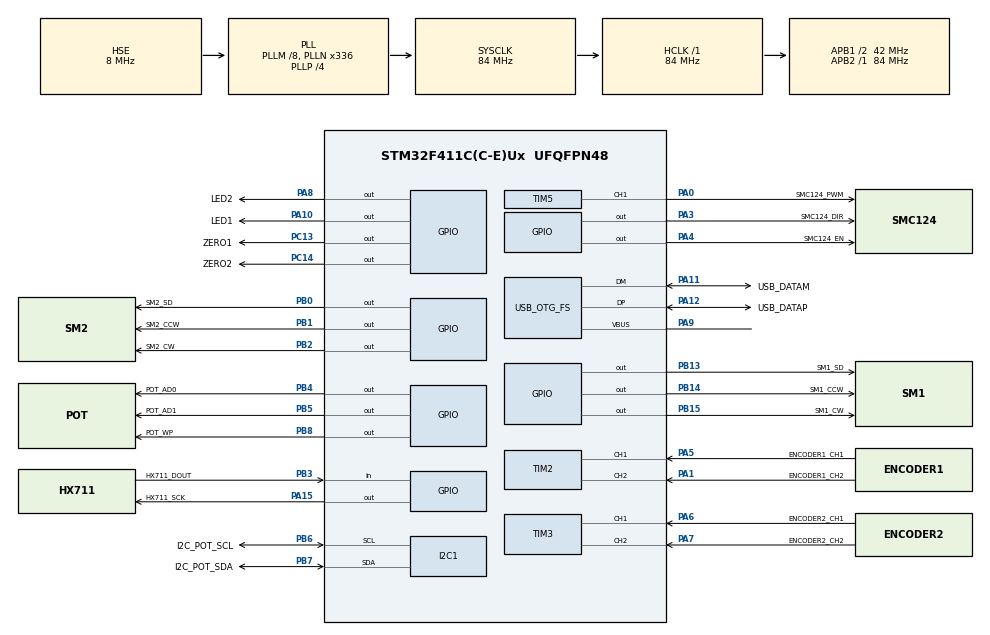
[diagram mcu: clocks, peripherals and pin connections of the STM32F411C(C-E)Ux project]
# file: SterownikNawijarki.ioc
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Mcu.Family=STM32F4
Mcu.Name=STM32F411C(C-E)Ux
Mcu.Package=UFQFPN48
NVIC.OTG_FS_IRQn=true\:0\:0\:false\:false\:true\:false\:true\:true
NVIC.PriorityGroup=NVIC_PRIORITYGROUP_4
NVIC.TIM4_IRQn=true\:0\:0\:false\:false\:true\:true\:true\:true
PA0-WKUP.GPIO_Label=SMC124_PWM
PA0-WKUP.Signal=S_TIM5_CH1
PA1.GPIO_Label=ENCODER1_CH2
PA1.Signal=S_TIM2_CH2
PA10.GPIO_Label=LED1
PA10.Signal=GPIO_Output
PA11.GPIO_Label=USB_DATAM
PA11.Mode=Device_Only
PA11.Signal=USB_OTG_FS_DM
PA12.GPIO_Label=USB_DATAP
PA12.Mode=Device_Only
PA12.Signal=USB_OTG_FS_DP
PA13.Mode=Serial_Wire
PA13.Signal=SYS_JTMS-SWDIO
PA14.Mode=Serial_Wire
PA14.Signal=SYS_JTCK-SWCLK
PA15.GPIO_Label=HX711_SCK
PA15.Signal=GPIO_Output
PA3.GPIO_Label=SMC124_DIR
PA3.Signal=GPIO_Output
PA4.GPIO_Label=SMC124_EN
PA4.Signal=GPIO_Output
PA5.GPIO_Label=ENCODER1_CH1
PA5.Signal=S_TIM2_CH1_ETR
PA6.GPIO_Label=ENCODER2_CH1
PA6.Signal=S_TIM3_CH1
PA7.GPIO_Label=ENCODER2_CH2
PA7.Signal=S_TIM3_CH2
PA8.GPIO_Label=LED2
PA8.Signal=GPIO_Output
PA9.Mode=Activate_VBUS
PA9.Signal=USB_OTG_FS_VBUS
PB0.GPIO_Label=SM2_SD
PB0.Signal=GPIO_Output
PB1.GPIO_Label=SM2_CCW
PB1.Signal=GPIO_Output
PB13.GPIO_Label=SM1_SD
PB13.Signal=GPIO_Output
PB14.GPIO_Label=SM1_CCW
PB14.Signal=GPIO_Output
PB15.GPIO_Label=SM1_CW
PB15.Signal=GPIO_Output
PB2.GPIO_Label=SM2_CW
PB2.Signal=GPIO_Output
PB3.GPIO_Label=HX711_DOUT
PB3.Signal=GPIO_Input
PB4.GPIO_Label=POT_AD0
PB4.Signal=GPIO_Output
PB5.GPIO_Label=POT_AD1
PB5.Signal=GPIO_Output
PB6.GPIO_Label=I2C_POT_SCL
PB6.Mode=I2C
PB6.Signal=I2C1_SCL
PB7.GPIO_Label=I2C_POT_SDA
PB7.Mode=I2C
PB7.Signal=I2C1_SDA
PB8.GPIO_Label=POT_WP
PB8.Signal=GPIO_Output
PC13-ANTI_TAMP.GPIO_Label=ZERO1
PC13-ANTI_TAMP.Signal=GPIO_Output
PC14-OSC32_IN.GPIO_Label=ZERO2
PC14-OSC32_IN.Signal=GPIO_Output
PH0\ -\ OSC_IN.GPIO_Label=OSC8M_IN
PH0\ -\ OSC_IN.Mode=HSE-External-Oscillator
PH0\ -\ OSC_IN.Signal=RCC_OSC_IN
PH1\ -\ OSC_OUT.GPIO_Label=OSC8M_OUT
PH1\ -\ OSC_OUT.Mode=HSE-External-Oscillator
PH1\ -\ OSC_OUT.Signal=RCC_OSC_OUT
ProjectManager.HeapSize=0x200
ProjectManager.StackSize=0x400
ProjectManager.TargetToolchain=STM32CubeIDE
RCC.48MHZClocksFreq_Value=48000000
RCC.AHBFreq_Value=84000000
RCC.APB1CLKDivider=RCC_HCLK_DIV2
RCC.APB1Freq_Value=42000000
RCC.APB1TimFreq_Value=84000000
RCC.APB2Freq_Value=84000000
RCC.APB2TimFreq_Value=84000000
RCC.CortexFreq_Value=84000000
RCC.HCLKFreq_Value=84000000
RCC.HSE_VALUE=8000000
RCC.HSI_VALUE=16000000
RCC.LSE_VALUE=32768
RCC.PLLM=8
RCC.PLLN=336
RCC.PLLP=RCC_PLLP_DIV4
RCC.PLLQ=7
RCC.SYSCLKFreq_VALUE=84000000
RCC.SYSCLKSource=RCC_SYSCLKSOURCE_PLLCLK
RCC.VCOOutputFreq_Value=336000000
SH.S_TIM2_CH1_ETR.0=TIM2_CH1,Encoder_Interface
SH.S_TIM2_CH2.0=TIM2_CH2,Encoder_Interface
SH.S_TIM3_CH1.0=TIM3_CH1,Encoder_Interface
SH.S_TIM3_CH2.0=TIM3_CH2,Encoder_Interface
SH.S_TIM5_CH1.0=TIM5_CH1,PWM Generation1 CH1
TIM4.AutoReloadPreload=TIM_AUTORELOAD_PRELOAD_ENABLE
TIM4.ClockDivision=TIM_CLOCKDIVISION_DIV4
TIM4.Period=9999
TIM4.Prescaler=8399
TIM5.Channel-PWM\ Generation1\ CH1=TIM_CHANNEL_1
TIM5.Period=99
TIM5.Prescaler=8
USB_DEVICE.CLASS_NAME_FS=CDC
USB_DEVICE.VirtualMode=Cdc
USB_DEVICE.VirtualModeFS=Cdc_FS
USB_OTG_FS.VirtualMode=Device_Only
VP_TIM4_VS_ClockSourceINT.Mode=Internal
VP_USB_DEVICE_VS_USB_DEVICE_CDC_FS.Mode=CDC_FS
board=custom

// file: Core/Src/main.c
/* USER CODE BEGIN Header */
/**
  ******************************************************************************
  * @file           : main.c
  * @brief          : Main program body
  ******************************************************************************
  * @attention
  *
  * Copyright (c) 2024 STMicroelectronics.
  * All rights reserved.
  *
  * This software is licensed under terms that can be found in the LICENSE file
  * in the root directory of this software component.
  * If no LICENSE file comes with this software, it is provided AS-IS.
  *
  ******************************************************************************
  */
/* USER CODE END Header */
#include "main.h"
#include "usb_device.h"

/* USER CODE BEGIN Includes */
#include "usbd_cdc_if.h"
#include "cdc_control.h"
#include "ad5254.h"
/* USER CODE END Includes */

I2C_HandleTypeDef hi2c1;

TIM_HandleTypeDef htim2;
TIM_HandleTypeDef htim3;
TIM_HandleTypeDef htim4;
TIM_HandleTypeDef htim5;

void SystemClock_Config(void);
static void MX_GPIO_Init(void);
static void MX_TIM2_Init(void);
static void MX_TIM3_Init(void);
static void MX_TIM5_Init(void);
static void MX_I2C1_Init(void);
static void MX_TIM4_Init(void);

int main(void)
{

  /* MCU Configuration--------------------------------------------------------*/

  /* Reset of all peripherals, Initializes the Flash interface and the Systick. */
  HAL_Init();

  /* Configure the system clock */
  SystemClock_Config();

  /* Initialize all configured peripherals */
  MX_GPIO_Init();
  MX_TIM2_Init();
  MX_TIM3_Init();
  MX_TIM5_Init();
  MX_USB_DEVICE_Init();
  MX_I2C1_Init();
  MX_TIM4_Init();

  /* Infinite loop */
  while (1)
  {

  }
}

void SystemClock_Config(void)
{
  RCC_OscInitTypeDef RCC_OscInitStruct = {0};
  RCC_ClkInitTypeDef RCC_ClkInitStruct = {0};

  /** Configure the main internal regulator output voltage
  */
  __HAL_RCC_PWR_CLK_ENABLE();
  __HAL_PWR_VOLTAGESCALING_CONFIG(PWR_REGULATOR_VOLTAGE_SCALE1);

  /** Initializes the RCC Oscillators according to the specified parameters
  * in the RCC_OscInitTypeDef structure.
  */
  RCC_OscInitStruct.OscillatorType = RCC_OSCILLATORTYPE_HSE;
  RCC_OscInitStruct.HSEState = RCC_HSE_ON;
  RCC_OscInitStruct.PLL.PLLState = RCC_PLL_ON;
  RCC_OscInitStruct.PLL.PLLSource = RCC_PLLSOURCE_HSE;
  RCC_OscInitStruct.PLL.PLLM = 8;
  RCC_OscInitStruct.PLL.PLLN = 336;
  RCC_OscInitStruct.PLL.PLLP = RCC_PLLP_DIV4;
  RCC_OscInitStruct.PLL.PLLQ = 7;
  if (HAL_RCC_OscConfig(&RCC_OscInitStruct) != HAL_OK)
  {
    Error_Handler();
  }

  /** Initializes the CPU, AHB and APB buses clocks
  */
  RCC_ClkInitStruct.ClockType = RCC_CLOCKTYPE_HCLK|RCC_CLOCKTYPE_SYSCLK
                              |RCC_CLOCKTYPE_PCLK1|RCC_CLOCKTYPE_PCLK2;
  RCC_ClkInitStruct.SYSCLKSource = RCC_SYSCLKSOURCE_PLLCLK;
  RCC_ClkInitStruct.AHBCLKDivider = RCC_SYSCLK_DIV1;
  RCC_ClkInitStruct.APB1CLKDivider = RCC_HCLK_DIV2;
  RCC_ClkInitStruct.APB2CLKDivider = RCC_HCLK_DIV1;

  if (HAL_RCC_ClockConfig(&RCC_ClkInitStruct, FLASH_LATENCY_2) != HAL_OK)
  {
    Error_Handler();
  }
}

static void MX_I2C1_Init(void)
{

  hi2c1.Instance = I2C1;
  hi2c1.Init.ClockSpeed = 100000;
  hi2c1.Init.DutyCycle = I2C_DUTYCYCLE_2;
  hi2c1.Init.OwnAddress1 = 0;
  hi2c1.Init.AddressingMode = I2C_ADDRESSINGMODE_7BIT;
  hi2c1.Init.DualAddressMode = I2C_DUALADDRESS_DISABLE;
  hi2c1.Init.OwnAddress2 = 0;
  hi2c1.Init.GeneralCallMode = I2C_GENERALCALL_DISABLE;
  hi2c1.Init.NoStretchMode = I2C_NOSTRETCH_DISABLE;
  if (HAL_I2C_Init(&hi2c1) != HAL_OK)
  {
    Error_Handler();
  }

}

static void MX_TIM2_Init(void)
{

  TIM_Encoder_InitTypeDef sConfig = {0};
  TIM_MasterConfigTypeDef sMasterConfig = {0};

  htim2.Instance = TIM2;
  htim2.Init.Prescaler = 0;
  htim2.Init.CounterMode = TIM_COUNTERMODE_UP;
  htim2.Init.Period = 4294967295;
  htim2.Init.ClockDivision = TIM_CLOCKDIVISION_DIV1;
  htim2.Init.AutoReloadPreload = TIM_AUTORELOAD_PRELOAD_DISABLE;
  sConfig.EncoderMode = TIM_ENCODERMODE_TI1;
  sConfig.IC1Polarity = TIM_ICPOLARITY_RISING;
  sConfig.IC1Selection = TIM_ICSELECTION_DIRECTTI;
  sConfig.IC1Prescaler = TIM_ICPSC_DIV1;
  sConfig.IC1Filter = 0;
  sConfig.IC2Polarity = TIM_ICPOLARITY_RISING;
  sConfig.IC2Selection = TIM_ICSELECTION_DIRECTTI;
  sConfig.IC2Prescaler = TIM_ICPSC_DIV1;
  sConfig.IC2Filter = 0;
  if (HAL_TIM_Encoder_Init(&htim2, &sConfig) != HAL_OK)
  {
    Error_Handler();
  }
  sMasterConfig.MasterOutputTrigger = TIM_TRGO_RESET;
  sMasterConfig.MasterSlaveMode = TIM_MASTERSLAVEMODE_DISABLE;
  if (HAL_TIMEx_MasterConfigSynchronization(&htim2, &sMasterConfig) != HAL_OK)
  {
    Error_Handler();
  }

}

static void MX_TIM3_Init(void)
{

  TIM_Encoder_InitTypeDef sConfig = {0};
  TIM_MasterConfigTypeDef sMasterConfig = {0};

  htim3.Instance = TIM3;
  htim3.Init.Prescaler = 0;
  htim3.Init.CounterMode = TIM_COUNTERMODE_UP;
  htim3.Init.Period = 65535;
  htim3.Init.ClockDivision = TIM_CLOCKDIVISION_DIV1;
  htim3.Init.AutoReloadPreload = TIM_AUTORELOAD_PRELOAD_DISABLE;
  sConfig.EncoderMode = TIM_ENCODERMODE_TI1;
  sConfig.IC1Polarity = TIM_ICPOLARITY_RISING;
  sConfig.IC1Selection = TIM_ICSELECTION_DIRECTTI;
  sConfig.IC1Prescaler = TIM_ICPSC_DIV1;
  sConfig.IC1Filter = 0;
  sConfig.IC2Polarity = TIM_ICPOLARITY_RISING;
  sConfig.IC2Selection = TIM_ICSELECTION_DIRECTTI;
  sConfig.IC2Prescaler = TIM_ICPSC_DIV1;
  sConfig.IC2Filter = 0;
  if (HAL_TIM_Encoder_Init(&htim3, &sConfig) != HAL_OK)
  {
    Error_Handler();
  }
  sMasterConfig.MasterOutputTrigger = TIM_TRGO_RESET;
  sMasterConfig.MasterSlaveMode = TIM_MASTERSLAVEMODE_DISABLE;
  if (HAL_TIMEx_MasterConfigSynchronization(&htim3, &sMasterConfig) != HAL_OK)
  {
    Error_Handler();
  }

}

static void MX_TIM4_Init(void)
{

  TIM_ClockConfigTypeDef sClockSourceConfig = {0};
  TIM_MasterConfigTypeDef sMasterConfig = {0};

  htim4.Instance = TIM4;
  htim4.Init.Prescaler = 8399;
  htim4.Init.CounterMode = TIM_COUNTERMODE_UP;
  htim4.Init.Period = 9999;
  htim4.Init.ClockDivision = TIM_CLOCKDIVISION_DIV4;
  htim4.Init.AutoReloadPreload = TIM_AUTORELOAD_PRELOAD_ENABLE;
  if (HAL_TIM_Base_Init(&htim4) != HAL_OK)
  {
    Error_Handler();
  }
  sClockSourceConfig.ClockSource = TIM_CLOCKSOURCE_INTERNAL;
  if (HAL_TIM_ConfigClockSource(&htim4, &sClockSourceConfig) != HAL_OK)
  {
    Error_Handler();
  }
  sMasterConfig.MasterOutputTrigger = TIM_TRGO_RESET;
  sMasterConfig.MasterSlaveMode = TIM_MASTERSLAVEMODE_DISABLE;
  if (HAL_TIMEx_MasterConfigSynchronization(&htim4, &sMasterConfig) != HAL_OK)
  {
    Error_Handler();
  }

}

static void MX_TIM5_Init(void)
{

  TIM_MasterConfigTypeDef sMasterConfig = {0};
  TIM_OC_InitTypeDef sConfigOC = {0};

  htim5.Instance = TIM5;
  htim5.Init.Prescaler = 8;
  htim5.Init.CounterMode = TIM_COUNTERMODE_UP;
  htim5.Init.Period = 99;
  htim5.Init.ClockDivision = TIM_CLOCKDIVISION_DIV1;
  htim5.Init.AutoReloadPreload = TIM_AUTORELOAD_PRELOAD_DISABLE;
  if (HAL_TIM_PWM_Init(&htim5) != HAL_OK)
  {
    Error_Handler();
  }
  sMasterConfig.MasterOutputTrigger = TIM_TRGO_RESET;
  sMasterConfig.MasterSlaveMode = TIM_MASTERSLAVEMODE_DISABLE;
  if (HAL_TIMEx_MasterConfigSynchronization(&htim5, &sMasterConfig) != HAL_OK)
  {
    Error_Handler();
  }
  sConfigOC.OCMode = TIM_OCMODE_PWM1;
  sConfigOC.Pulse = 0;
  sConfigOC.OCPolarity = TIM_OCPOLARITY_HIGH;
  sConfigOC.OCFastMode = TIM_OCFAST_DISABLE;
  if (HAL_TIM_PWM_ConfigChannel(&htim5, &sConfigOC, TIM_CHANNEL_1) != HAL_OK)
  {
    Error_Handler();
  }
  HAL_TIM_MspPostInit(&htim5);

}

static void MX_GPIO_Init(void)
{
  GPIO_InitTypeDef GPIO_InitStruct = {0};

  /* GPIO Ports Clock Enable */
  __HAL_RCC_GPIOC_CLK_ENABLE();
  __HAL_RCC_GPIOH_CLK_ENABLE();
  __HAL_RCC_GPIOA_CLK_ENABLE();
  __HAL_RCC_GPIOB_CLK_ENABLE();

  /*Configure GPIO pin Output Level */
  HAL_GPIO_WritePin(GPIOC, ZERO1_Pin|ZERO2_Pin, GPIO_PIN_RESET);

  /*Configure GPIO pin Output Level */
  HAL_GPIO_WritePin(GPIOA, SMC124_DIR_Pin|SMC124_EN_Pin|LED2_Pin|LED1_Pin
                          |HX711_SCK_Pin, GPIO_PIN_RESET);

  /*Configure GPIO pin Output Level */
  HAL_GPIO_WritePin(GPIOB, SM2_SD_Pin|SM2_CCW_Pin|SM2_CW_Pin|SM1_SD_Pin
                          |SM1_CCW_Pin|SM1_CW_Pin|POT_AD0_Pin|POT_AD1_Pin
                          |POT_WP_Pin, GPIO_PIN_RESET);

  /*Configure GPIO pins : ZERO1_Pin ZERO2_Pin */
  GPIO_InitStruct.Pin = ZERO1_Pin|ZERO2_Pin;
  GPIO_InitStruct.Mode = GPIO_MODE_OUTPUT_PP;
  GPIO_InitStruct.Pull = GPIO_NOPULL;
  GPIO_InitStruct.Speed = GPIO_SPEED_FREQ_LOW;
  HAL_GPIO_Init(GPIOC, &GPIO_InitStruct);

  /*Configure GPIO pins : SMC124_DIR_Pin SMC124_EN_Pin LED2_Pin LED1_Pin
                           HX711_SCK_Pin */
  GPIO_InitStruct.Pin = SMC124_DIR_Pin|SMC124_EN_Pin|LED2_Pin|LED1_Pin
                          |HX711_SCK_Pin;
  GPIO_InitStruct.Mode = GPIO_MODE_OUTPUT_PP;
  GPIO_InitStruct.Pull = GPIO_NOPULL;
  GPIO_InitStruct.Speed = GPIO_SPEED_FREQ_LOW;
  HAL_GPIO_Init(GPIOA, &GPIO_InitStruct);

  /*Configure GPIO pins : SM2_SD_Pin SM2_CCW_Pin SM2_CW_Pin SM1_SD_Pin
                           SM1_CCW_Pin SM1_CW_Pin POT_AD0_Pin POT_AD1_Pin
                           POT_WP_Pin */
  GPIO_InitStruct.Pin = SM2_SD_Pin|SM2_CCW_Pin|SM2_CW_Pin|SM1_SD_Pin
                          |SM1_CCW_Pin|SM1_CW_Pin|POT_AD0_Pin|POT_AD1_Pin
                          |POT_WP_Pin;
  GPIO_InitStruct.Mode = GPIO_MODE_OUTPUT_PP;
  GPIO_InitStruct.Pull = GPIO_NOPULL;
  GPIO_InitStruct.Speed = GPIO_SPEED_FREQ_LOW;
  HAL_GPIO_Init(GPIOB, &GPIO_InitStruct);

  /*Configure GPIO pin : HX711_DOUT_Pin */
  GPIO_InitStruct.Pin = HX711_DOUT_Pin;
  GPIO_InitStruct.Mode = GPIO_MODE_INPUT;
  GPIO_InitStruct.Pull = GPIO_NOPULL;
  HAL_GPIO_Init(HX711_DOUT_GPIO_Port, &GPIO_InitStruct);

/* USER CODE BEGIN MX_GPIO_Init_2 */
  HAL_GPIO_WritePin(GPIOA, LED2_Pin|LED1_Pin , GPIO_PIN_SET);
/* USER CODE END MX_GPIO_Init_2 */
}

void Error_Handler(void)
{
  __disable_irq();
  while (1)
  {
  }
}
